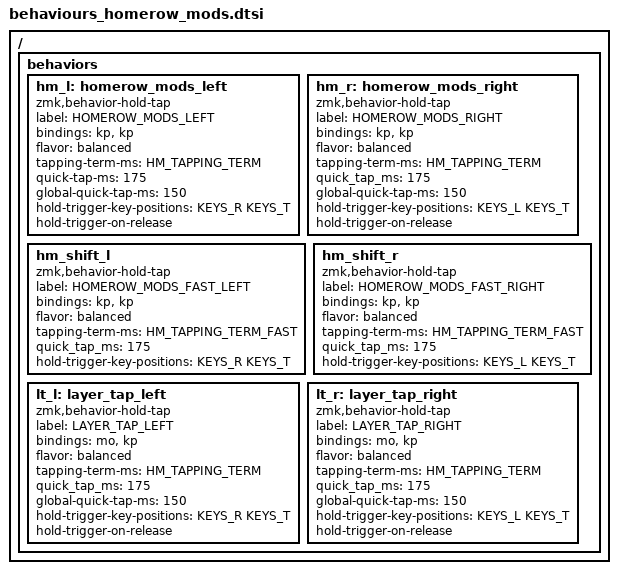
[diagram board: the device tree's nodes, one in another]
// Make sure settings.dtsi is included before this file

#include "../../zmk-nodefree-config/keypos_def/keypos_adv360.h"
#define KEYS_L LN0 LN1 LN2 LN3 LN4 LN5 LT0 LT1 LT2 LT3 LT4 LT5 LM0 LM1 LM2 LM3 LM4 LM5 LB0 LB1 LB2 LB3 LB4 LB5
#define KEYS_R RN0 RN1 RN2 RN3 RN4 RN5 RT0 RT1 RT2 RT3 RT4 RT5 RM0 RM1 RM2 RM3 RM4 RM5 RB0 RB1 RB2 RB3 RB4 RB5
#define KEYS_T LH1 LH0 RH0 RH1

#define HM_TAPPING_TERM 200
#define HM_TAPPING_TERM_FAST 135

/ {

    behaviors {

        // Positional Homerow mods
        // Homerow mods that prevent accidental activations when rolling keys,
        // such as when typing `st` or `ne` on colemak-dh layouts or `as` on
        // qwerty.
        //
        // Works by only allowing a mod to activate within tapping-term if
        // it's on the opposite side of the keyboard or on the same side thumb
        // keys.

        // Further optimization using urob's timerless homerow mods method:
        // https://github.com/urob/zmk-config#timeless-homerow-mods
        hm_l: homerow_mods_left {
            compatible = "zmk,behavior-hold-tap";
            label = "HOMEROW_MODS_LEFT";
            #binding-cells = <2>;
            bindings = <&kp>,  <&kp>;

            flavor = "balanced";
            tapping-term-ms = <HM_TAPPING_TERM>;
            quick-tap-ms = <175>;                // repeat on tap-into-hold
            global-quick-tap-ms = <150>;         // requires PR #1387
            hold-trigger-key-positions = <KEYS_R KEYS_T>;
            hold-trigger-on-release;             // requires PR #1423
        };

        hm_r: homerow_mods_right {
            compatible = "zmk,behavior-hold-tap";
            label = "HOMEROW_MODS_RIGHT";
            #binding-cells = <2>;
            bindings = <&kp>, <&kp>;

            flavor = "balanced";
            tapping-term-ms = <HM_TAPPING_TERM>;
            quick_tap_ms = <175>;
            global-quick-tap-ms = <150>;         // requires PR #1387
            hold-trigger-key-positions = <KEYS_L KEYS_T>;
            hold-trigger-on-release;             // requires PR #1423
        };


        // Positional Homerow mods for shift
        // Use faster tapping term and disable some features that may
        // cause false negatives.
        hm_shift_l: hm_shift_l {
            compatible = "zmk,behavior-hold-tap";
            label = "HOMEROW_MODS_FAST_LEFT";
            #binding-cells = <2>;
            bindings = <&kp>, <&kp>;

            flavor = "balanced";
            tapping-term-ms = <HM_TAPPING_TERM_FAST>;
            quick_tap_ms = <175>;
            // global-quick-tap-ms = <150>;         // requires PR #1387
            hold-trigger-key-positions = <KEYS_R KEYS_T>;
            // hold-trigger-on-release;             // requires PR #1423
        };

        hm_shift_r: hm_shift_r {
            compatible = "zmk,behavior-hold-tap";
            label = "HOMEROW_MODS_FAST_RIGHT";
            #binding-cells = <2>;
            bindings = <&kp>, <&kp>;

            flavor = "balanced";
            tapping-term-ms = <HM_TAPPING_TERM_FAST>;
            quick_tap_ms = <175>;
            // global-quick-tap-ms = <150>;         // requires PR #1387
            hold-trigger-key-positions = <KEYS_L KEYS_T>;
            // hold-trigger-on-release;             // requires PR #1423
        };

        lt_l: layer_tap_left {
            compatible = "zmk,behavior-hold-tap";
            label = "LAYER_TAP_LEFT";
            #binding-cells = <2>;
            bindings = <&mo>, <&kp>;
            flavor = "balanced";
            tapping-term-ms = <HM_TAPPING_TERM>;
            quick_tap_ms = <175>;
            global-quick-tap-ms = <150>;         // requires PR #1387
            hold-trigger-key-positions = <KEYS_R KEYS_T>;
            hold-trigger-on-release;             // requires PR #1423
        };

        lt_r: layer_tap_right {
            compatible = "zmk,behavior-hold-tap";
            label = "LAYER_TAP_RIGHT";
            #binding-cells = <2>;
            bindings = <&mo>, <&kp>;
            flavor = "balanced";
            tapping-term-ms = <HM_TAPPING_TERM>;
            quick_tap_ms = <175>;
            global-quick-tap-ms = <150>;         // requires PR #1387
            hold-trigger-key-positions = <KEYS_L KEYS_T>;
            hold-trigger-on-release;             // requires PR #1423
        };

    };
};
